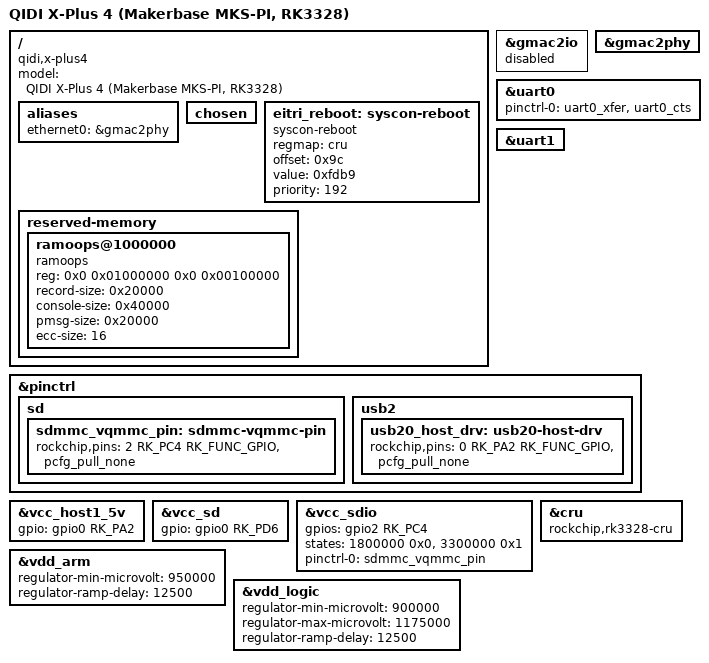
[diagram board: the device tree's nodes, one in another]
// SPDX-License-Identifier: GPL-2.0+ OR MIT
/*
 * QIDI X-Plus 4 host board: a Makerbase MKS-PI (Rockchip RK3328), which is a
 * ROC-RK3328-CC derivative.
 *
 * The mainline ROC-RK3328-CC device tree is the base. This file overrides only
 * what differs on the QIDI board. Every difference below was read from the
 * device tree that the stock image ships (model "Makerbase mks-pi") and from
 * the upstream tree it is applied to, and none of it has been booted yet:
 * rk3328-roc-cc.dts and this file must be validated on the bench, from a
 * microSD card, before any image is written to the eMMC.
 *
 *   - Ethernet: the MKS-PI uses the SoC's internal 100 Mbit PHY (gmac2phy).
 *     The ROC-CC's external RGMII PHY (gmac2io) is not populated.
 *   - UARTs: uart0 and uart1 are enabled next to uart2, giving ttyS0, ttyS1
 *     and ttyS2. They carry the two MCUs and the touchscreen; which board is
 *     on which port is decided at run time, so none of them is a console (the
 *     ROC-CC debug console is uart2).
 *   - Power switches: the microSD VCC switch is active high, the USB host 5 V
 *     enable is GPIO0_PA2, and the SD I/O voltage select is GPIO2_PC4. The
 *     ROC-CC drives these from different pins and polarities.
 */

#include "rockchip/rk3328-roc-cc.dts"

/ {
	model = "QIDI X-Plus 4 (Makerbase MKS-PI, RK3328)";
	compatible = "qidi,x-plus4", "firefly,roc-rk3328-cc", "rockchip,rk3328";

	aliases {
		ethernet0 = &gmac2phy;
	};

	/*
	 * The UARTs belong to the MCUs and the screen. Without stdout-path the
	 * kernel never selects one as a console even if "console=" is absent.
	 */
	chosen {
		/delete-property/ stdout-path;
	};
};

&gmac2io {
	status = "disabled";
};

&gmac2phy {
	status = "okay";
};

/*
 * uart0 uses TX/RX and CTS only on this board; RTS stays a GPIO. uart1 keeps
 * the full upstream pin group.
 */
&uart0 {
	pinctrl-names = "default";
	pinctrl-0 = <&uart0_xfer &uart0_cts>;
	status = "okay";
};

&uart1 {
	status = "okay";
};

&pinctrl {
	sd {
		sdmmc_vqmmc_pin: sdmmc-vqmmc-pin {
			rockchip,pins = <2 RK_PC4 RK_FUNC_GPIO &pcfg_pull_none>;
		};
	};

	usb2 {
		/* USB host VBUS enable moved from GPIO1_PD2 to GPIO0_PA2. */
		usb20_host_drv: usb20-host-drv {
			rockchip,pins = <0 RK_PA2 RK_FUNC_GPIO &pcfg_pull_none>;
		};
	};
};

&vcc_host1_5v {
	gpio = <&gpio0 RK_PA2 GPIO_ACTIVE_HIGH>;
};

&vcc_sd {
	gpio = <&gpio0 RK_PD6 GPIO_ACTIVE_HIGH>;
};

&vcc_sdio {
	gpios = <&gpio2 RK_PC4 GPIO_ACTIVE_HIGH>;
	states = <1800000 0x0>, <3300000 0x1>;
	pinctrl-names = "default";
	pinctrl-0 = <&sdmmc_vqmmc_pin>;
};

/*
 * Reliable warm reboot (bench-validate; not yet booted).
 *
 * The stock ARM Trusted Firmware that Eitri keeps does not reset the RK3328 on a
 * PSCI SYSTEM_RESET: `reboot` issues the SMC, the firmware hangs in EL3, and the
 * kernel has no other reset path, so a warm reboot hangs while a cold power-on
 * always works. systemd's watchdog fallback (RebootWatchdogSec) is not honoured
 * by this build, so nothing recovers it but a power cut.
 *
 * Reset the SoC directly instead: the CRU first global software reset
 * (CRU_GLB_SRST_FST, offset 0x9c, magic 0xfdb9) resets the whole chip. The clock
 * driver already writes the CRU from the non-secure kernel, so EL1 can reach this
 * register too; adding "syscon" to the CRU node lets syscon-reboot map it. The
 * handler's priority (192) is above PSCI's (129), so the register write is tried
 * before the SMC. If the write turns out to be ignored (secure-gated), reboot is
 * no worse than today -- it simply falls through to PSCI. The clock driver still
 * binds on the first compatible string, so clocking and boot are unchanged.
 *
 * Validate on the bench from microSD: after this DTB boots, `reboot` must bring
 * the board back by itself, and the screen (console=tty1) must pass
 * "reboot: Restarting system" without hanging.
 */
&cru {
	compatible = "rockchip,rk3328-cru", "syscon";
};

/ {
	eitri_reboot: syscon-reboot {
		compatible = "syscon-reboot";
		regmap = <&cru>;
		offset = <0x9c>;
		value = <0xfdb9>;
		priority = <192>;
	};
};

/*
 * Crash records across a reset (bench-validate; not yet booted).
 *
 * ramoops keeps the kernel log of a panic (the lockup detectors in linux.fragment
 * turn a frozen CPU into one) and the console in this RAM, which a watchdog or CRU
 * reset does not clear; systemd-pstore moves the records into the journal on the
 * next boot. A power cut loses them.
 *
 * Placement: below 0x200000 is the boot firmware's (Linux's RAM starts there on this
 * board, /proc/iomem), and U-Boot itself runs from 0x200000 before it relocates.
 * U-Boot then loads into 0x500000 (scriptaddr), 0x600000 (pxefile_addr_r), 0x1e00000
 * (fdt), 0x1f00000 (overlays), 0x2080000 (kernel) and 0x6000000 (ramdisk); 16 MiB is
 * clear of all of them, so a boot does not overwrite the previous crash.
 * os/tests/test_tree.py checks that against uboot.env.
 */
/ {
	reserved-memory {
		#address-cells = <2>;
		#size-cells = <2>;
		ranges;

		ramoops@1000000 {
			compatible = "ramoops";
			reg = <0x0 0x01000000 0x0 0x00100000>;
			record-size = <0x20000>;
			console-size = <0x40000>;
			pmsg-size = <0x20000>;
			ecc-size = <16>;
		};
	};
};

/*
 * CPU and logic rail ramp delay (bench-validate; suspected cause of the 2026-10-24 freezes).
 *
 * The RK805's DCDC regulators take time to reach a new voltage. Without regulator-ramp-delay
 * the kernel assumes the change is instant, so cpufreq raises the CPU clock while vdd_arm is
 * still ramping up, and for a few microseconds the cores run faster than their voltage
 * supports: a classic cause of silent RK3328 hard freezes (no panic, no log line, screen
 * frozen, network gone), which is what the printer did twice that day, once idle. The
 * mainline ROC-RK3328-CC board file this tree builds on does not set it; the stock QIDI
 * device tree ("Makerbase mks-pi") and mainline's rk3328-rock64.dts both use 12500 uV/us.
 * The voltage windows are the stock ones too: the OPP tables need 0.95-1.30 V on vdd_arm
 * and 1.075 V on vdd_logic, and the stock tree never let the rails outside that.
 */
&vdd_arm {
	regulator-min-microvolt = <950000>;
	regulator-ramp-delay = <12500>;
};

&vdd_logic {
	regulator-min-microvolt = <900000>;
	regulator-max-microvolt = <1175000>;
	regulator-ramp-delay = <12500>;
};
